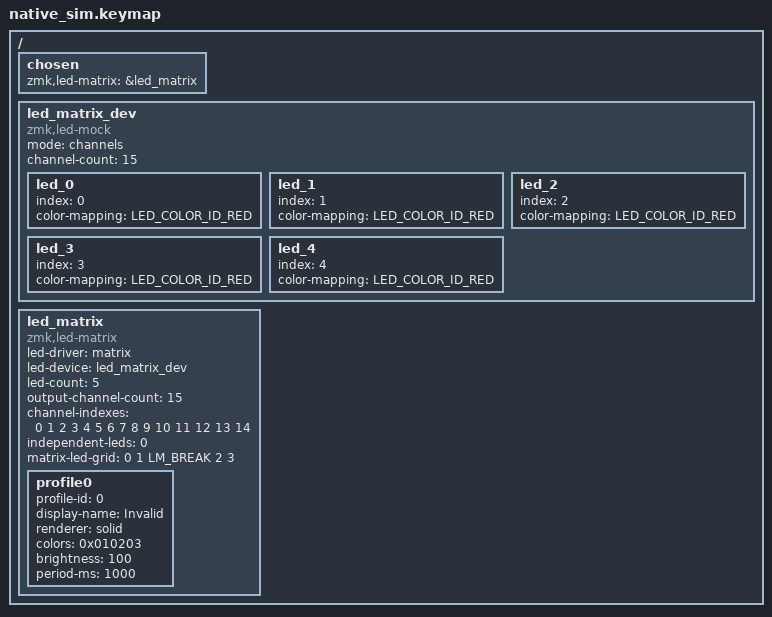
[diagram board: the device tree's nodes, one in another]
#include "../behavior_keymap.dtsi"

/ {
    chosen {
        zmk,led-matrix = &led_matrix;
    };

    led_matrix_dev: led_matrix_dev {
        compatible = "zmk,led-mock";
        mode = "channels";
        channel-count = <15>;

        led_0 { index = <0>; color-mapping = <LED_COLOR_ID_RED>; };
        led_1 { index = <1>; color-mapping = <LED_COLOR_ID_RED>; };
        led_2 { index = <2>; color-mapping = <LED_COLOR_ID_RED>; };
        led_3 { index = <3>; color-mapping = <LED_COLOR_ID_RED>; };
        led_4 { index = <4>; color-mapping = <LED_COLOR_ID_RED>; };
    };

    led_matrix: led_matrix {
        compatible = "zmk,led-matrix";
        led-driver = "matrix";
        led-device = <&led_matrix_dev>;
        led-count = <5>;
        output-channel-count = <15>;
        channel-indexes = <
            0 1 2
            3 4 5
            6 7 8
            9 10 11
            12 13 14
        >;
        independent-leds = <0>;
        matrix-led-grid = <
            0 1 LM_BREAK
            2 3
        >;

        profile0 {
            profile-id = <0>;
            display-name = "Invalid";
            renderer = "solid";
            colors = <0x010203>;
            brightness = <100>;
            period-ms = <1000>;
        };
    };
};
